AUTOSAR XML (schema 4-2-2)
package /Components
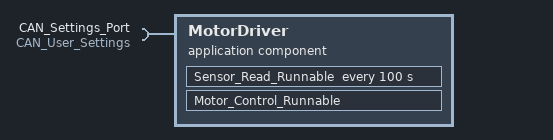
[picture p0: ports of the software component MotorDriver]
  application sw component type MotorDriver
    provide/require port MotorCommand_Port: provided-required-interface=WiperControl_To_MotorDriver
    provide/require port Status_Port: provided-required-interface=RainSensor_To_WiperController
    require port CAN_Settings_Port: required-interface=CAN_User_Settings
    behavior MotorDriver_Behavior
      internal trigger occurred event HardwareFeedbackEvent: start-on-event=Sensor_Read_Runnable, event-source=HardwareFeedback
      timing event DriverWatchdogEvent: start-on-event=Sensor_Read_Runnable, period=100
      runnable Motor_Control_Runnable: minimum-start-interval=20, symbol=MotorDriver_Motor_Control
        data-receive-point-by-arguments:
          access Receive_Control_Arguments: accessed-variable=MotorCommand_Port.ControlCommandArg
        data-send-points:
          access Send_Status: accessed-variable=Status_Port.MotorStatus
        sync call HAL_Call_Point: operation=MotorCommand_Port.HardwareControlOp, timeout=20
